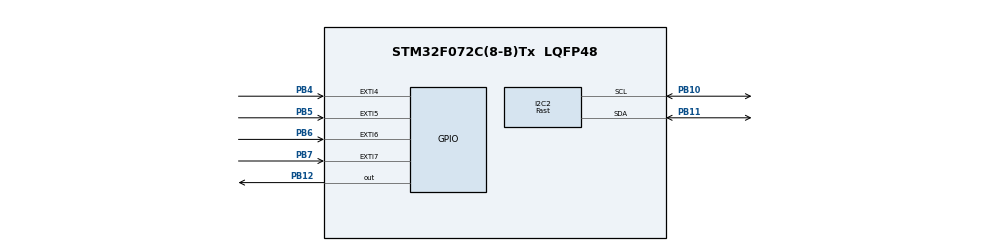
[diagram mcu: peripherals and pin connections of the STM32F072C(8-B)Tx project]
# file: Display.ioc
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Dma.I2C2_TX.0.Direction=DMA_MEMORY_TO_PERIPH
Dma.I2C2_TX.0.Instance=DMA1_Channel4
Dma.I2C2_TX.0.MemDataAlignment=DMA_MDATAALIGN_BYTE
Dma.I2C2_TX.0.MemInc=DMA_MINC_ENABLE
Dma.I2C2_TX.0.Mode=DMA_NORMAL
Dma.I2C2_TX.0.PeriphDataAlignment=DMA_PDATAALIGN_BYTE
Dma.I2C2_TX.0.PeriphInc=DMA_PINC_DISABLE
Dma.I2C2_TX.0.Priority=DMA_PRIORITY_LOW
Dma.Request0=I2C2_TX
I2C2.I2C_Speed_Mode=I2C_Fast
I2C2.Timing=0x0000020B
Mcu.Family=STM32F0
Mcu.Name=STM32F072C(8-B)Tx
Mcu.Package=LQFP48
NVIC.DMA1_Channel4_5_6_7_IRQn=true\:0\:0\:false\:false\:true\:false\:true\:true
NVIC.EXTI4_15_IRQn=true\:0\:0\:false\:false\:true\:true\:true\:true
NVIC.I2C2_IRQn=true\:0\:0\:false\:false\:true\:true\:true\:true
PB10.Mode=I2C
PB10.Signal=I2C2_SCL
PB11.Mode=I2C
PB11.Signal=I2C2_SDA
PB12.Signal=GPIO_Output
PB4.GPIO_ModeDefaultEXTI=GPIO_MODE_IT_FALLING
PB4.GPIO_PuPd=GPIO_PULLUP
PB4.Signal=GPXTI4
PB5.GPIO_ModeDefaultEXTI=GPIO_MODE_IT_FALLING
PB5.GPIO_PuPd=GPIO_PULLUP
PB5.Signal=GPXTI5
PB6.GPIO_ModeDefaultEXTI=GPIO_MODE_IT_FALLING
PB6.GPIO_PuPd=GPIO_PULLUP
PB6.Signal=GPXTI6
PB7.GPIO_ModeDefaultEXTI=GPIO_MODE_IT_FALLING
PB7.GPIO_PuPd=GPIO_PULLUP
PB7.Signal=GPXTI7
PF0-OSC_IN.Mode=HSE-External-Clock-Source
PF0-OSC_IN.Signal=RCC_OSC_IN
ProjectManager.HeapSize=0x200
ProjectManager.StackSize=0x400
ProjectManager.TargetToolchain=EWARM V8.32
board=custom

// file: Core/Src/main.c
/* USER CODE BEGIN Header */
/**
  ******************************************************************************
  * @file           : main.c
  * @brief          : Main program body
  ******************************************************************************
  * @attention
  *
  * Copyright (c) 2025 STMicroelectronics.
  * All rights reserved.
  *
  * This software is licensed under terms that can be found in the LICENSE file
  * in the root directory of this software component.
  * If no LICENSE file comes with this software, it is provided AS-IS.
  *
  ******************************************************************************
  */
/* USER CODE END Header */
#include "main.h"

/* USER CODE BEGIN Includes */
#include "MySH1106.h"
#include "tree.h"
#include "fonts.h"
/* USER CODE END Includes */

I2C_HandleTypeDef hi2c2;
DMA_HandleTypeDef hdma_i2c2_tx;

void SystemClock_Config(void);
static void MX_GPIO_Init(void);
static void MX_DMA_Init(void);
static void MX_I2C2_Init(void);

int main(void)
{

  /* MCU Configuration--------------------------------------------------------*/

  /* Reset of all peripherals, Initializes the Flash interface and the Systick. */
  HAL_Init();

  /* Configure the system clock */
  SystemClock_Config();

  /* Initialize all configured peripherals */
  MX_GPIO_Init();
  MX_DMA_Init();
  MX_I2C2_Init();
  /* USER CODE BEGIN 2 */

  HAL_GPIO_WritePin(GPIOB, GPIO_PIN_12, GPIO_PIN_RESET);

  SH1106_Init();

  current_screen = &Welcome_Screen;

  current_screen->Render_Screen_on_Frame_Buffer();

  SH1106_Start_Update();
  /* USER CODE END 2 */

  /* Infinite loop */
  while (1)
  {

    /* USER CODE BEGIN 3 */

    SH1106_I2C_Update_Frame_loop();

    Switch_Screens_Loop();

  }
  /* USER CODE END 3 */
}

void SystemClock_Config(void)
{
  RCC_OscInitTypeDef RCC_OscInitStruct = {0};
  RCC_ClkInitTypeDef RCC_ClkInitStruct = {0};

  /** Initializes the RCC Oscillators according to the specified parameters
  * in the RCC_OscInitTypeDef structure.
  */
  RCC_OscInitStruct.OscillatorType = RCC_OSCILLATORTYPE_HSI;
  RCC_OscInitStruct.HSIState = RCC_HSI_ON;
  RCC_OscInitStruct.HSICalibrationValue = RCC_HSICALIBRATION_DEFAULT;
  RCC_OscInitStruct.PLL.PLLState = RCC_PLL_NONE;
  if (HAL_RCC_OscConfig(&RCC_OscInitStruct) != HAL_OK)
  {
    Error_Handler();
  }

  /** Initializes the CPU, AHB and APB buses clocks
  */
  RCC_ClkInitStruct.ClockType = RCC_CLOCKTYPE_HCLK|RCC_CLOCKTYPE_SYSCLK
                              |RCC_CLOCKTYPE_PCLK1;
  RCC_ClkInitStruct.SYSCLKSource = RCC_SYSCLKSOURCE_HSI;
  RCC_ClkInitStruct.AHBCLKDivider = RCC_SYSCLK_DIV1;
  RCC_ClkInitStruct.APB1CLKDivider = RCC_HCLK_DIV1;

  if (HAL_RCC_ClockConfig(&RCC_ClkInitStruct, FLASH_LATENCY_0) != HAL_OK)
  {
    Error_Handler();
  }
}

static void MX_I2C2_Init(void)
{

  hi2c2.Instance = I2C2;
  hi2c2.Init.Timing = 0x0000020B;
  hi2c2.Init.OwnAddress1 = 0;
  hi2c2.Init.AddressingMode = I2C_ADDRESSINGMODE_7BIT;
  hi2c2.Init.DualAddressMode = I2C_DUALADDRESS_DISABLE;
  hi2c2.Init.OwnAddress2 = 0;
  hi2c2.Init.OwnAddress2Masks = I2C_OA2_NOMASK;
  hi2c2.Init.GeneralCallMode = I2C_GENERALCALL_DISABLE;
  hi2c2.Init.NoStretchMode = I2C_NOSTRETCH_DISABLE;
  if (HAL_I2C_Init(&hi2c2) != HAL_OK)
  {
    Error_Handler();
  }

  /** Configure Analogue filter
  */
  if (HAL_I2CEx_ConfigAnalogFilter(&hi2c2, I2C_ANALOGFILTER_ENABLE) != HAL_OK)
  {
    Error_Handler();
  }

  /** Configure Digital filter
  */
  if (HAL_I2CEx_ConfigDigitalFilter(&hi2c2, 0) != HAL_OK)
  {
    Error_Handler();
  }

}

static void MX_DMA_Init(void)
{

  /* DMA controller clock enable */
  __HAL_RCC_DMA1_CLK_ENABLE();

  /* DMA interrupt init */
  /* DMA1_Channel4_5_6_7_IRQn interrupt configuration */
  HAL_NVIC_SetPriority(DMA1_Channel4_5_6_7_IRQn, 0, 0);
  HAL_NVIC_EnableIRQ(DMA1_Channel4_5_6_7_IRQn);

}

static void MX_GPIO_Init(void)
{
  GPIO_InitTypeDef GPIO_InitStruct = {0};

  /* GPIO Ports Clock Enable */
  __HAL_RCC_GPIOF_CLK_ENABLE();
  __HAL_RCC_GPIOB_CLK_ENABLE();

  /*Configure GPIO pin Output Level */
  HAL_GPIO_WritePin(GPIOB, GPIO_PIN_12, GPIO_PIN_RESET);

  /*Configure GPIO pin : PB12 */
  GPIO_InitStruct.Pin = GPIO_PIN_12;
  GPIO_InitStruct.Mode = GPIO_MODE_OUTPUT_PP;
  GPIO_InitStruct.Pull = GPIO_NOPULL;
  GPIO_InitStruct.Speed = GPIO_SPEED_FREQ_LOW;
  HAL_GPIO_Init(GPIOB, &GPIO_InitStruct);

  /*Configure GPIO pins : PB4 PB5 PB6 PB7 */
  GPIO_InitStruct.Pin = GPIO_PIN_4|GPIO_PIN_5|GPIO_PIN_6|GPIO_PIN_7;
  GPIO_InitStruct.Mode = GPIO_MODE_IT_FALLING;
  GPIO_InitStruct.Pull = GPIO_PULLUP;
  HAL_GPIO_Init(GPIOB, &GPIO_InitStruct);

  /* EXTI interrupt init*/
  HAL_NVIC_SetPriority(EXTI4_15_IRQn, 0, 0);
  HAL_NVIC_EnableIRQ(EXTI4_15_IRQn);

}

void Error_Handler(void)
{
  __disable_irq();
  while (1)
  {
  }
}
